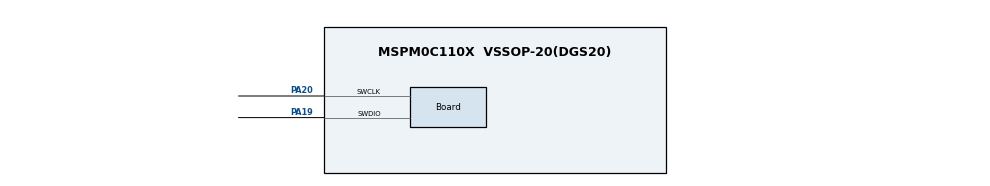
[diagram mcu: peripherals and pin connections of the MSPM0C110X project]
// @cliArgs --device "MSPM0C110X" --package "VSSOP-20(DGS20)" --part "Default"
// @cliArgs --board /ti/boards/LP_MSPM0C1104 --rtos nortos

/**
 * Import the modules used in this configuration.
 */
const Board  = scripting.addModule("/ti/driverlib/Board");
const GPIO   = scripting.addModule("/ti/driverlib/GPIO", {}, false);
const GPIO1  = GPIO.addInstance();
const SYSCTL = scripting.addModule("/ti/driverlib/SYSCTL");
const TIMER  = scripting.addModule("/ti/driverlib/TIMER", {}, false);
const TIMER1 = TIMER.addInstance();
const WWDT   = scripting.addModule("/ti/driverlib/WWDT", {}, false);
const WWDT1  = WWDT.addInstance();

/**
 * Write custom configuration values to the imported modules.
 */
Board.peripheral.$assign          = "DEBUGSS";
Board.peripheral.swclkPin.$assign = "PA20";
Board.peripheral.swdioPin.$assign = "PA19";

GPIO1.$name                          = "GPIO_LEDS";
GPIO1.associatedPins.create(2);
GPIO1.associatedPins[0].$name        = "USER_LED_1";
GPIO1.associatedPins[0].initialValue = "SET";
GPIO1.associatedPins[0].assignedPin  = "22";
GPIO1.associatedPins[1].$name        = "USER_TEST";
GPIO1.associatedPins[1].assignedPin  = "2";
GPIO1.associatedPins[1].initialValue = "SET";

SYSCTL.clockTreeEn = true;

TIMER1.$name              = "TIMER_0";
TIMER1.timerClkPrescale   = 256;
TIMER1.timerMode          = "PERIODIC";
TIMER1.interrupts         = ["ZERO"];
TIMER1.timerPeriod        = "50 ms";
TIMER1.peripheral.$assign = "TIMA0";

WWDT1.$name              = "WWDT0";
WWDT1.wwdtMode           = "INTERVAL";
WWDT1.sleepMode          = true;
WWDT1.enabledInterrupts  = true;
WWDT1.peripheral.$assign = "WWDT0";
